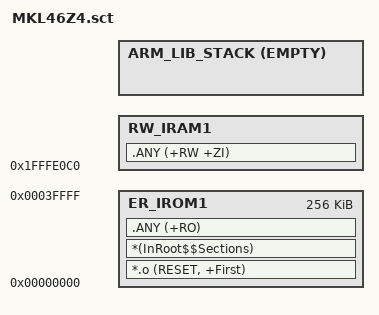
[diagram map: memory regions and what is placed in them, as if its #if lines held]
#! armcc -E
#include "mbed_config.h"

#if (defined(__stack_size__))
  #define Stack_Size                   __stack_size__
#else
  #if (defined(MBED_CONF_RTOS_PRESENT))
    #define Stack_Size                   0x0400
  #else
    #define Stack_Size                   0x1000
  #endif
#endif

LR_IROM1 0x00000000 0x40000  {    ; load region size_region (256k)
  ER_IROM1 0x00000000 0x40000  {  ; load address = execution address
   *.o (RESET, +First)
   *(InRoot$$Sections)
   .ANY (+RO)
  }
  ; 8_byte_aligned(48 vect * 4 bytes) =  8_byte_aligned(0xC0) = 0xC0
  ; 0x8000 - 0xC0 = 0x7F40
  RW_IRAM1 0x1FFFE0C0 0x7F40 - Stack_Size {
   .ANY (+RW +ZI)
  }
  ARM_LIB_STACK 0x1FFFE0C0 + 0x7F40 EMPTY -Stack_Size { ; Stack region growing down
  }
}

